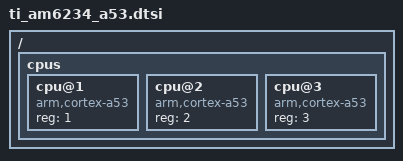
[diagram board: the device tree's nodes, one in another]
/*
 * Copyright (c) 2023 Enphase Energy
 *
 * SPDX-License-Identifier: Apache-2.0
 */

#include <arm64/ti/ti_am62x_a53.dtsi>

/ {
	cpus {
		#address-cells = <1>;
		#size-cells = <0>;

		cpu@1 {
			compatible = "arm,cortex-a53";
			reg = <1>;
			device_type = "cpu";
		};

		cpu@2 {
			compatible = "arm,cortex-a53";
			reg = <2>;
			device_type = "cpu";
		};

		cpu@3 {
			compatible = "arm,cortex-a53";
			reg = <3>;
			device_type = "cpu";
		};
	};
};
